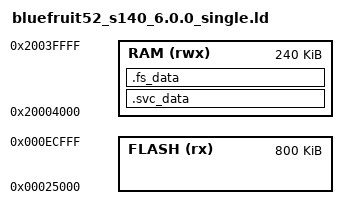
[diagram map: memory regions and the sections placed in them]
/* Linker script to configure memory regions. */

SEARCH_DIR(.)
GROUP(-lgcc -lc -lnosys)

MEMORY
{
  FLASH (rx) : ORIGIN = 0x25000, LENGTH = 0xC8000 /* Max 800 KB for single bank */

  /* SRAM required by S140 depends on:
   * - Attribute Table Size
   * - Vendor UUID count
   * - Max ATT MTU
   * - Concurrent connection peripheral + central + secure links
   * - Event Len, HVN queue, Write CMD queue
   *
   * 16 KB reserved here, leaving 240KB free
   */ 
  RAM (rwx) :  ORIGIN = 0x20004000, LENGTH = 0x20040000 - 0x20004000
}

SECTIONS
{
  . = ALIGN(4);
  .svc_data :
  {
    PROVIDE(__start_svc_data = .);
    KEEP(*(.svc_data))
    PROVIDE(__stop_svc_data = .);
  } > RAM
  
  .fs_data :
  {
    PROVIDE(__start_fs_data = .);
    KEEP(*(.fs_data))
    PROVIDE(__stop_fs_data = .);
  } > RAM
} INSERT AFTER .data;

INCLUDE "nrf5x_common.ld"
